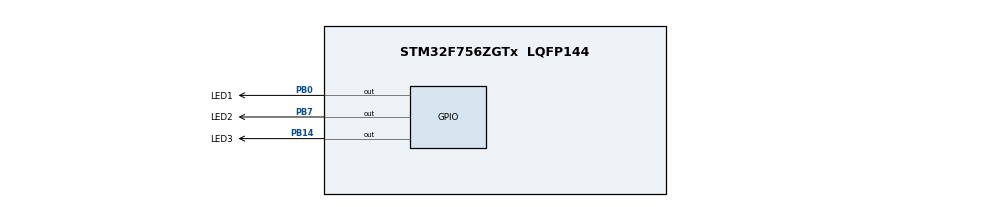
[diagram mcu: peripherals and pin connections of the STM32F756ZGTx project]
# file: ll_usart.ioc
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Mcu.Family=STM32F7
Mcu.Name=STM32F756ZGTx
Mcu.Package=LQFP144
NVIC.PriorityGroup=NVIC_PRIORITYGROUP_4
PB0.GPIO_Label=LED1
PB0.Signal=GPIO_Output
PB14.GPIO_Label=LED3
PB14.Signal=GPIO_Output
PB7.GPIO_Label=LED2
PB7.Signal=GPIO_Output
ProjectManager.HeapSize=0x200
ProjectManager.StackSize=0x400
ProjectManager.TargetToolchain=STM32CubeIDE
RCC.HSE_VALUE=25000000
RCC.HSI_VALUE=16000000
RCC.LSE_VALUE=32768
RCC.USBFreq_Value=96000000
RCC.VCOOutputFreq_Value=192000000
board=custom

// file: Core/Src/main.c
/* USER CODE BEGIN Header */
/**
 ******************************************************************************
 * @file           : main.c
 * @brief          : Main program body
 ******************************************************************************
 * @attention
 *
 * Copyright (c) 2023 STMicroelectronics.
 * All rights reserved.
 *
 * This software is licensed under terms that can be found in the LICENSE file
 * in the root directory of this software component.
 * If no LICENSE file comes with this software, it is provided AS-IS.
 *
 ******************************************************************************
 */
/* USER CODE END Header */
#include "main.h"
#include "gpio.h"

void SystemClock_Config(void);
/* USER CODE BEGIN PFP */
void USART3_Init();
/* USER CODE END PFP */

int main(void)
{

  /* MCU Configuration--------------------------------------------------------*/

  /* Reset of all peripherals, Initializes the Flash interface and the Systick. */

  LL_APB1_GRP1_EnableClock(LL_APB1_GRP1_PERIPH_PWR);
  LL_APB2_GRP1_EnableClock(LL_APB2_GRP1_PERIPH_SYSCFG);

  /* System interrupt init*/
  NVIC_SetPriorityGrouping(NVIC_PRIORITYGROUP_4);

  /* SysTick_IRQn interrupt configuration */
  NVIC_SetPriority(SysTick_IRQn, NVIC_EncodePriority(NVIC_GetPriorityGrouping(), 15, 0));

  /* Configure the system clock */
  SystemClock_Config();

  /* Initialize all configured peripherals */
  MX_GPIO_Init();
  USART3_Init();

  /* Infinite loop */
  /* USER CODE BEGIN WHILE */
  uint8_t data[7] = "limka\r\n";
  for (uint8_t i = 0; i < sizeof(data); i++)
  {
    while (!LL_USART_IsActiveFlag_TXE(USART3))
      ;
    LL_USART_TransmitData8(USART3, data[i]);
  }

  typedef struct
  {
    uint8_t data[32];
    uint8_t count;
  } buffer_t;
  buffer_t rx_buffer = {0};

  while (1)
  {
    /* USER CODE END WHILE */

    /* USER CODE BEGIN 3 */
    if (LL_USART_IsActiveFlag_RXNE(USART3))
    {
      rx_buffer.data[rx_buffer.count] = LL_USART_ReceiveData8(USART3);

      if (LL_USART_IsActiveFlag_TXE(USART3))
      {
        LL_USART_TransmitData8(USART3, rx_buffer.data[rx_buffer.count]);
      }
      rx_buffer.count++;
    }
  }
  /* USER CODE END 3 */
}

void SystemClock_Config(void)
{
  LL_FLASH_SetLatency(LL_FLASH_LATENCY_0);
  while (LL_FLASH_GetLatency() != LL_FLASH_LATENCY_0)
  {
  }
  LL_PWR_SetRegulVoltageScaling(LL_PWR_REGU_VOLTAGE_SCALE3);
  /*while (LL_PWR_IsActiveFlag_VOS() == 0)
  {
  }*/
  LL_PWR_DisableOverDriveMode();
  LL_RCC_HSI_SetCalibTrimming(16);
  LL_RCC_HSI_Enable();

  /* Wait till HSI is ready */
  while (LL_RCC_HSI_IsReady() != 1)
  {
  }
  LL_RCC_SetAHBPrescaler(LL_RCC_SYSCLK_DIV_1);
  LL_RCC_SetAPB1Prescaler(LL_RCC_APB1_DIV_1);
  LL_RCC_SetAPB2Prescaler(LL_RCC_APB2_DIV_1);
  LL_RCC_SetSysClkSource(LL_RCC_SYS_CLKSOURCE_HSI);

  /* Wait till System clock is ready */
  while (LL_RCC_GetSysClkSource() != LL_RCC_SYS_CLKSOURCE_STATUS_HSI)
  {
  }
  LL_Init1msTick(16000000);
  LL_SetSystemCoreClock(16000000);
}

/* USER CODE BEGIN 4 */
void USART3_Init()
{
  LL_RCC_SetUSARTClockSource(LL_RCC_USART3_CLKSOURCE_PCLK1);
  LL_APB1_GRP1_EnableClock(LL_APB1_GRP1_PERIPH_USART3);
  LL_AHB1_GRP1_EnableClock(LL_AHB1_GRP1_PERIPH_GPIOD);

  LL_GPIO_SetPinMode(GPIOD, LL_GPIO_PIN_8, LL_GPIO_MODE_ALTERNATE);
  LL_GPIO_SetPinPull(GPIOD, LL_GPIO_PIN_8, LL_GPIO_PULL_NO);
  LL_GPIO_SetPinSpeed(GPIOD, LL_GPIO_PIN_8, LL_GPIO_SPEED_FREQ_VERY_HIGH);
  LL_GPIO_SetAFPin_8_15(GPIOD, LL_GPIO_PIN_8, LL_GPIO_AF_7);

  LL_GPIO_SetPinMode(GPIOD, LL_GPIO_PIN_9, LL_GPIO_MODE_ALTERNATE);
  LL_GPIO_SetPinPull(GPIOD, LL_GPIO_PIN_9, LL_GPIO_PULL_NO);
  LL_GPIO_SetPinSpeed(GPIOD, LL_GPIO_PIN_9, LL_GPIO_SPEED_FREQ_VERY_HIGH);
  LL_GPIO_SetAFPin_8_15(GPIOD, LL_GPIO_PIN_9, LL_GPIO_AF_7);

  LL_USART_ConfigCharacter(USART3, LL_USART_DATAWIDTH_8B, LL_USART_PARITY_NONE, LL_USART_STOPBITS_1);
  LL_USART_SetOverSampling(USART3, LL_USART_OVERSAMPLING_8);
  LL_USART_SetBaudRate(USART3, SystemCoreClock, LL_USART_OVERSAMPLING_8, 115200U);
  LL_USART_EnableDirectionTx(USART3);
  LL_USART_EnableDirectionRx(USART3);
  LL_USART_ConfigAsyncMode(USART3);
  LL_USART_Enable(USART3);
}
/* USER CODE END 4 */

void Error_Handler(void)
{
  __disable_irq();
  while (1)
  {
  }
}
